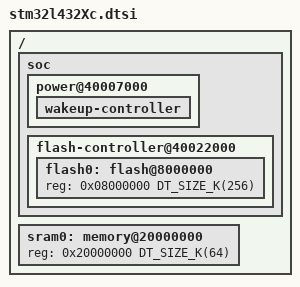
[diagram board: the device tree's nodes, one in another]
/*
 * Copyright (c) 2018 Linaro Limited
 *
 * SPDX-License-Identifier: Apache-2.0
 */
#include <st/l4/stm32l432.dtsi>

/ {
	soc {
		/*
		 * STM32L432xx exists only in UFQFPN32 package
		 * where PC13/WKUP2 and PC5/WKUP5 are not available
		 */
		power@40007000 {
			wakeup-controller {
				/delete-node/ wkup@2;
				/delete-node/ wkup@5;
			};
		};

		flash-controller@40022000 {
			flash0: flash@8000000 {
				reg = <0x08000000 DT_SIZE_K(256)>;
				ranges = <0 0x8000000 DT_SIZE_K(256)>;
			};
		};
	};

	sram0: memory@20000000 {
		reg = <0x20000000 DT_SIZE_K(64)>;
	};
};
